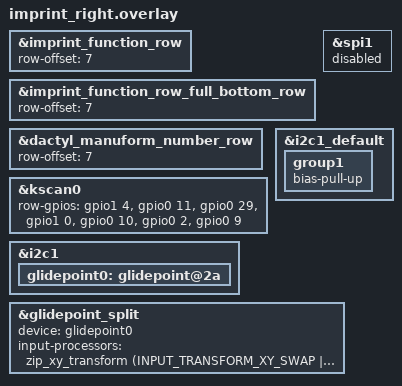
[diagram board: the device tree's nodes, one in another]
#include "imprint.dtsi"

&imprint_function_row { // The matrix transform for this board is 7 rows down because the left half is 7 rows tall according to the matrix.
    row-offset = <7>;
};

&imprint_function_row_full_bottom_row {
    row-offset = <7>;
};

&dactyl_manuform_number_row {
    row-offset = <7>;
};

&kscan0 {
    row-gpios
        = <&gpio1 4 GPIO_ACTIVE_HIGH> // row0 from schematic
        , <&gpio0 11 GPIO_ACTIVE_HIGH> // row1 from schematic
        , <&gpio0 29 GPIO_ACTIVE_HIGH> // row2 from schematic
        , <&gpio1 0 GPIO_ACTIVE_HIGH> // row3 from schematic
        , <&gpio0 10 GPIO_ACTIVE_HIGH> // row4 from schematic
        , <&gpio0 2 GPIO_ACTIVE_HIGH> // row5 from schematic
        , <&gpio0 9 GPIO_ACTIVE_HIGH> // row6 from schematic
        ;
};

#include <zephyr/dt-bindings/input/input-event-codes.h>
&spi1 {
    status = "disabled";

};

&i2c1 {
    status = "okay";
    glidepoint0: glidepoint@2a {
        status = "okay";
    };
};

&i2c1_default {
    group1 {
      bias-pull-up;
    };
};


// Overrides for the input-split child node
&glidepoint_split {
    device = <&glidepoint0>;

    // Optional
    input-processors = <&zip_xy_transform (INPUT_TRANSFORM_XY_SWAP | INPUT_TRANSFORM_X_INVERT | INPUT_TRANSFORM_Y_INVERT)>;
};
